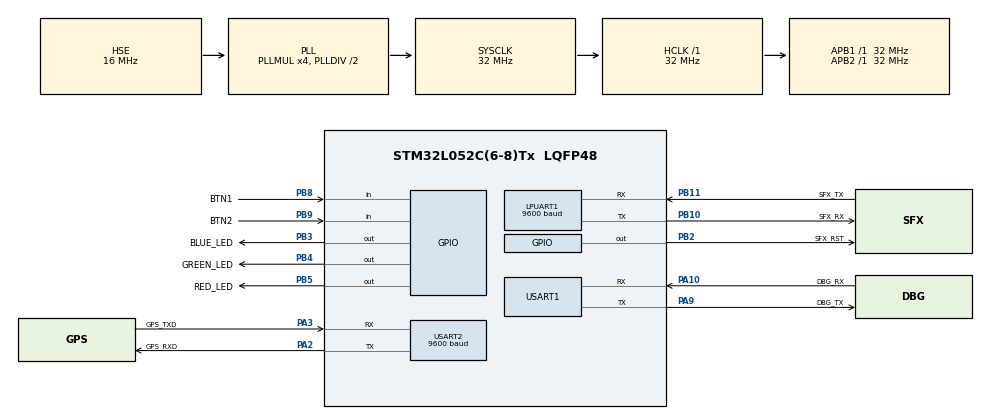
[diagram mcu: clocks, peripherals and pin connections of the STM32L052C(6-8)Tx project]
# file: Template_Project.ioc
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LPUART1.BaudRate=9600
LPUART1.WordLength=UART_WORDLENGTH_8B
Mcu.Family=STM32L0
Mcu.Name=STM32L052C(6-8)Tx
Mcu.Package=LQFP48
NVIC.RNG_LPUART1_IRQn=true\:0\:0\:false\:false\:true\:true\:true
NVIC.USART1_IRQn=true\:0\:0\:false\:false\:true\:true\:true
NVIC.USART2_IRQn=true\:0\:0\:false\:false\:true\:true\:true
PA10.GPIO_Label=DBG_RX
PA10.Mode=Asynchronous
PA10.Signal=USART1_RX
PA2.GPIO_Label=GPS_RXD
PA2.Mode=Asynchronous
PA2.Signal=USART2_TX
PA3.GPIO_Label=GPS_TXD
PA3.Mode=Asynchronous
PA3.Signal=USART2_RX
PA9.GPIO_Label=DBG_TX
PA9.Mode=Asynchronous
PA9.Signal=USART1_TX
PB10.GPIO_Label=SFX_RX
PB10.Mode=Asynchronous
PB10.Signal=LPUART1_TX
PB11.GPIO_Label=SFX_TX
PB11.Mode=Asynchronous
PB11.Signal=LPUART1_RX
PB2.GPIO_Label=SFX_RST
PB2.GPIO_PuPd=GPIO_PULLUP
PB2.Signal=GPIO_Output
PB3.GPIO_Label=BLUE_LED
PB3.Signal=GPIO_Output
PB4.GPIO_Label=GREEN_LED
PB4.Signal=GPIO_Output
PB5.GPIO_Label=RED_LED
PB5.Signal=GPIO_Output
PB8.GPIO_Label=BTN1
PB8.Signal=GPIO_Input
PB9.GPIO_Label=BTN2
PB9.Signal=GPIO_Input
PH0-OSC_IN.Mode=HSE-External-Oscillator
PH0-OSC_IN.Signal=RCC_OSC_IN
PH1-OSC_OUT.Mode=HSE-External-Oscillator
PH1-OSC_OUT.Signal=RCC_OSC_OUT
ProjectManager.HeapSize=0x200
ProjectManager.StackSize=0x400
ProjectManager.TargetToolchain=STM32CubeIDE
RCC.AHBFreq_Value=32000000
RCC.APB1Freq_Value=32000000
RCC.APB1TimFreq_Value=32000000
RCC.APB2Freq_Value=32000000
RCC.APB2TimFreq_Value=32000000
RCC.HCLKFreq_Value=32000000
RCC.HSE_VALUE=16000000
RCC.HSI16_VALUE=16000000
RCC.HSI48_VALUE=48000000
RCC.HSI_VALUE=16000000
RCC.LSE_VALUE=32768
RCC.MSI_VALUE=2097000
RCC.PLLMUL=RCC_PLLMUL_4
RCC.PLLSourceVirtual=RCC_PLLSOURCE_HSE
RCC.SYSCLKFreq_VALUE=32000000
RCC.SYSCLKSource=RCC_SYSCLKSOURCE_PLLCLK
RCC.VCOOutputFreq_Value=64000000
USART1.VirtualMode-Asynchronous=VM_ASYNC
USART2.BaudRate=9600
USART2.VirtualMode-Asynchronous=VM_ASYNC
board=custom

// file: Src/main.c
/* USER CODE BEGIN Header */
/**
 ******************************************************************************
 * @file           : main.c
 * @brief          : Main program body
 ******************************************************************************
 * @attention
 *
 * <h2><center>&copy; Copyright (c) 2019 STMicroelectronics.
 * All rights reserved.</center></h2>
 *
 * This software component is licensed by ST under BSD 3-Clause license,
 * the "License"; You may not use this file except in compliance with the
 * License. You may obtain a copy of the License at:
 *                        opensource.org/licenses/BSD-3-Clause
 *
 ******************************************************************************
 */

/*
 * main.c
 *
 * Warefab Konnect STM32L0-SIGFOX Development Board
 *
 * Created on: Nov 8, 2019
 * Author: Muchiri John
 * (c) wwww.warefab.com
 *
 * This software component is licensed by warefab under BSD 3-Clause license,
 * the "License"; You may not use this file except in compliance with the
 * License. You may obtain a copy of the License at:
 *
 * opensource.org/licenses/BSD-3-Clause
 *
 */

#include <stdio.h>
#include <stdlib.h>
#include <math.h>
/* USER CODE END Header */

#include "main.h"
#include "usart.h"
#include "gpio.h"

/* USER CODE BEGIN Includes */
#include "sigfox.h"
/* USER CODE END Includes */

/* USER CODE BEGIN PV */
static const char NMEA_NONE[] =
		"$PMTK314,0,0,0,0,0,0,0,0,0,0,0,0,0,0,0,0,0,0,0*28\r\n";
/* USER CODE END PV */

void SystemClock_Config(void);

int main(void)
{

  /* MCU Configuration--------------------------------------------------------*/

  /* Reset of all peripherals, Initializes the Flash interface and the Systick. */
  HAL_Init();

  /* Configure the system clock */
  SystemClock_Config();

  /* Initialize all configured peripherals */
  MX_GPIO_Init();
  MX_LPUART1_UART_Init();
  MX_USART1_UART_Init();
  MX_USART2_UART_Init();
  /* USER CODE BEGIN 2 */
	//disable gps nmea output
	usart_puts(&huart2, (char *)NMEA_NONE);
	//reset sigfox module
	resetSigfoxModule();
  /* USER CODE END 2 */

  /* Infinite loop */
	while (1) {

	}
}

void SystemClock_Config(void)
{
  RCC_OscInitTypeDef RCC_OscInitStruct = {0};
  RCC_ClkInitTypeDef RCC_ClkInitStruct = {0};
  RCC_PeriphCLKInitTypeDef PeriphClkInit = {0};

  /** Configure the main internal regulator output voltage
  */
  __HAL_PWR_VOLTAGESCALING_CONFIG(PWR_REGULATOR_VOLTAGE_SCALE1);
  /** Initializes the CPU, AHB and APB busses clocks
  */
  RCC_OscInitStruct.OscillatorType = RCC_OSCILLATORTYPE_HSE;
  RCC_OscInitStruct.HSEState = RCC_HSE_ON;
  RCC_OscInitStruct.PLL.PLLState = RCC_PLL_ON;
  RCC_OscInitStruct.PLL.PLLSource = RCC_PLLSOURCE_HSE;
  RCC_OscInitStruct.PLL.PLLMUL = RCC_PLLMUL_4;
  RCC_OscInitStruct.PLL.PLLDIV = RCC_PLLDIV_2;
  if (HAL_RCC_OscConfig(&RCC_OscInitStruct) != HAL_OK)
  {
    Error_Handler();
  }
  /** Initializes the CPU, AHB and APB busses clocks
  */
  RCC_ClkInitStruct.ClockType = RCC_CLOCKTYPE_HCLK|RCC_CLOCKTYPE_SYSCLK
                              |RCC_CLOCKTYPE_PCLK1|RCC_CLOCKTYPE_PCLK2;
  RCC_ClkInitStruct.SYSCLKSource = RCC_SYSCLKSOURCE_PLLCLK;
  RCC_ClkInitStruct.AHBCLKDivider = RCC_SYSCLK_DIV1;
  RCC_ClkInitStruct.APB1CLKDivider = RCC_HCLK_DIV1;
  RCC_ClkInitStruct.APB2CLKDivider = RCC_HCLK_DIV1;

  if (HAL_RCC_ClockConfig(&RCC_ClkInitStruct, FLASH_LATENCY_1) != HAL_OK)
  {
    Error_Handler();
  }
  PeriphClkInit.PeriphClockSelection = RCC_PERIPHCLK_USART1|RCC_PERIPHCLK_USART2
                              |RCC_PERIPHCLK_LPUART1;
  PeriphClkInit.Usart1ClockSelection = RCC_USART1CLKSOURCE_PCLK2;
  PeriphClkInit.Usart2ClockSelection = RCC_USART2CLKSOURCE_PCLK1;
  PeriphClkInit.Lpuart1ClockSelection = RCC_LPUART1CLKSOURCE_PCLK1;
  if (HAL_RCCEx_PeriphCLKConfig(&PeriphClkInit) != HAL_OK)
  {
    Error_Handler();
  }
}

void Error_Handler(void)
{
}

/************************ (C) COPYRIGHT STMicroelectronics *****END OF FILE****/
